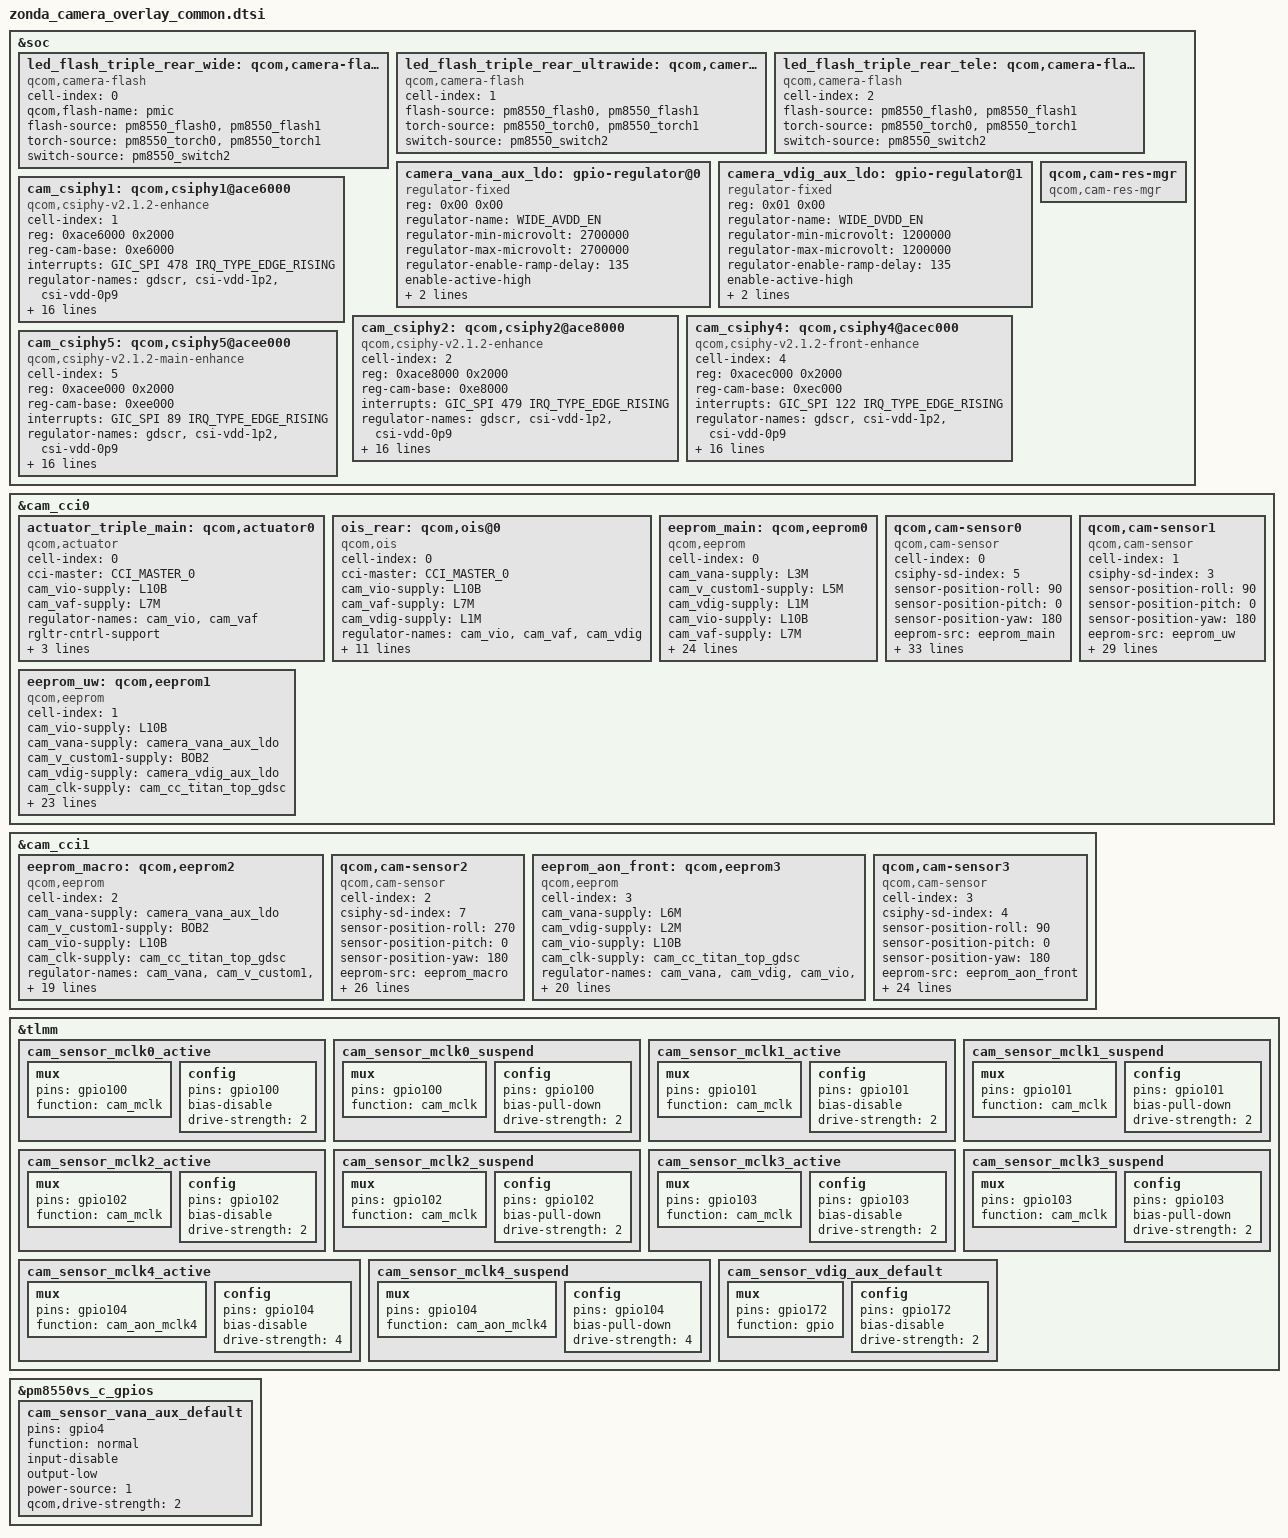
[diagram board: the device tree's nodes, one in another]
#include <dt-bindings/msm-camera.h>

&soc {
	led_flash_triple_rear_wide: qcom,camera-flash0 {
		cell-index = <0>;
		compatible = "qcom,camera-flash";
		qcom,flash-name = "pmic";
		flash-source = <&pm8550_flash0 &pm8550_flash1>;
		torch-source = <&pm8550_torch0 &pm8550_torch1>;
		switch-source = <&pm8550_switch2>;
		status = "ok";
	};

	led_flash_triple_rear_ultrawide: qcom,camera-flash1 {
		cell-index = <1>;
		compatible = "qcom,camera-flash";
		flash-source = <&pm8550_flash0 &pm8550_flash1>;
		torch-source = <&pm8550_torch0 &pm8550_torch1>;
		switch-source = <&pm8550_switch2>;
		status = "ok";
	};

	led_flash_triple_rear_tele: qcom,camera-flash2 {
		cell-index = <2>;
		compatible = "qcom,camera-flash";
		flash-source = <&pm8550_flash0 &pm8550_flash1>;
		torch-source = <&pm8550_torch0 &pm8550_torch1>;
		switch-source = <&pm8550_switch2>;
		status = "ok";
	};
	camera_vana_aux_ldo: gpio-regulator@0 {
		compatible = "regulator-fixed";
		reg = <0x00 0x00>;
		regulator-name = "WIDE_AVDD_EN";
		regulator-min-microvolt = <2700000>;
		regulator-max-microvolt = <2700000>;
		regulator-enable-ramp-delay = <135>;
		enable-active-high;
		gpio = <&pm8550vs_c_gpios 4 0>;
		pinctrl-names = "default";
		pinctrl-0 = <&cam_sensor_vana_aux_default>;
		//vin-supply = <&BOB>;
	};
	camera_vdig_aux_ldo: gpio-regulator@1 {
		compatible = "regulator-fixed";
		reg = <0x01 0x00>;
		regulator-name = "WIDE_DVDD_EN";
		regulator-min-microvolt = <1200000>;
		regulator-max-microvolt = <1200000>;
		regulator-enable-ramp-delay = <135>;
		enable-active-high;
		gpio = <&tlmm 172 0>;
		pinctrl-names = "default";
		pinctrl-0 = <&cam_sensor_vdig_aux_default>;
		//vin-supply = <&S4G>;
	};
	qcom,cam-res-mgr {
		compatible = "qcom,cam-res-mgr";
		status = "ok";
	};

	cam_csiphy1: qcom,csiphy1@ace6000 {
		cell-index = <1>;
		compatible = "qcom,csiphy-v2.1.2-enhance", "qcom,csiphy";
		reg = <0xace6000 0x2000>;
		reg-names = "csiphy";
		reg-cam-base = <0xe6000>;
		interrupt-names = "CSIPHY1";
		interrupts = <GIC_SPI 478 IRQ_TYPE_EDGE_RISING>;
		regulator-names = "gdscr", "csi-vdd-1p2", "csi-vdd-0p9";
		gdscr-supply = <&cam_cc_titan_top_gdsc>;
		csi-vdd-1p2-supply = <&L3E>;
		csi-vdd-0p9-supply = <&L1E>;
		rgltr-cntrl-support;
		rgltr-min-voltage = <0 1200000 875000>;
		rgltr-max-voltage = <0 1200000 925000>;
		rgltr-load-current = <0 18000 32200>;
		shared-clks = <1 0 0 0>;
		clock-names = "cphy_rx_clk_src",
			"csiphy1_clk",
			"csi1phytimer_clk_src",
			"csi1phytimer_clk";
		clocks = <&camcc CAM_CC_CPHY_RX_CLK_SRC>,
			<&camcc CAM_CC_CSIPHY1_CLK>,
			<&camcc CAM_CC_CSI1PHYTIMER_CLK_SRC>,
			<&camcc CAM_CC_CSI1PHYTIMER_CLK>;
		src-clock-name = "csi1phytimer_clk_src";
		clock-cntl-level = "lowsvs", "nominal";
		clock-rates =
			<400000000 0 400000000 0>,
			<480000000 0 400000000 0>;
		status = "ok";
	};

	cam_csiphy2: qcom,csiphy2@ace8000 {
		cell-index = <2>;
		compatible = "qcom,csiphy-v2.1.2-enhance", "qcom,csiphy";
		reg = <0xace8000 0x2000>;
		reg-names = "csiphy";
		reg-cam-base = <0xe8000>;
		interrupt-names = "CSIPHY2";
		interrupts = <GIC_SPI 479 IRQ_TYPE_EDGE_RISING>;
		regulator-names = "gdscr", "csi-vdd-1p2", "csi-vdd-0p9";
		gdscr-supply = <&cam_cc_titan_top_gdsc>;
		csi-vdd-1p2-supply = <&L3E>;
		csi-vdd-0p9-supply = <&L1E>;
		rgltr-cntrl-support;
		rgltr-min-voltage = <0 1200000 875000>;
		rgltr-max-voltage = <0 1200000 925000>;
		rgltr-load-current = <0 18000 32200>;
		shared-clks = <1 0 0 0>;
		clock-names = "cphy_rx_clk_src",
			"csiphy2_clk",
			"csi2phytimer_clk_src",
			"csi2phytimer_clk";
		clocks = <&camcc CAM_CC_CPHY_RX_CLK_SRC>,
			<&camcc CAM_CC_CSIPHY2_CLK>,
			<&camcc CAM_CC_CSI2PHYTIMER_CLK_SRC>,
			<&camcc CAM_CC_CSI2PHYTIMER_CLK>;
		src-clock-name = "csi2phytimer_clk_src";
		clock-cntl-level = "lowsvs", "nominal";
		clock-rates =
			<400000000 0 400000000 0>,
			<480000000 0 400000000 0>;
		status = "ok";
	};

	cam_csiphy4: qcom,csiphy4@acec000 {
		cell-index = <4>;
		compatible = "qcom,csiphy-v2.1.2-front-enhance", "qcom,csiphy";
		reg = <0xacec000 0x2000>;
		reg-names = "csiphy";
		reg-cam-base = <0xec000>;
		interrupt-names = "CSIPHY4";
		interrupts = <GIC_SPI 122 IRQ_TYPE_EDGE_RISING>;
		regulator-names = "gdscr", "csi-vdd-1p2", "csi-vdd-0p9";
		gdscr-supply = <&cam_cc_titan_top_gdsc>;
		csi-vdd-1p2-supply = <&L3E>;
		csi-vdd-0p9-supply = <&L1E>;
		rgltr-cntrl-support;
		rgltr-min-voltage = <0 1200000 875000>;
		rgltr-max-voltage = <0 1200000 925000>;
		rgltr-load-current = <0 18600 37900>;
		shared-clks = <1 0 0 0>;
		clock-names = "cphy_rx_clk_src",
			"csiphy4_clk",
			"csi4phytimer_clk_src",
			"csi4phytimer_clk";
		clocks = <&camcc CAM_CC_CPHY_RX_CLK_SRC>,
			<&camcc CAM_CC_CSIPHY4_CLK>,
			<&camcc CAM_CC_CSI4PHYTIMER_CLK_SRC>,
			<&camcc CAM_CC_CSI4PHYTIMER_CLK>;
		src-clock-name = "csi4phytimer_clk_src";
		clock-cntl-level = "lowsvs", "nominal";
		clock-rates =
			<400000000 0 400000000 0>,
			<480000000 0 400000000 0>;
		status = "ok";
	};

	cam_csiphy5: qcom,csiphy5@acee000 {
		cell-index = <5>;
		compatible = "qcom,csiphy-v2.1.2-main-enhance", "qcom,csiphy";
		reg = <0xacee000 0x2000>;
		reg-names = "csiphy";
		reg-cam-base = <0xee000>;
		interrupt-names = "CSIPHY5";
		interrupts = <GIC_SPI 89 IRQ_TYPE_EDGE_RISING>;
		regulator-names = "gdscr", "csi-vdd-1p2", "csi-vdd-0p9";
		gdscr-supply = <&cam_cc_titan_top_gdsc>;
		csi-vdd-1p2-supply = <&L3E>;
		csi-vdd-0p9-supply = <&L1E>;
		rgltr-cntrl-support;
		rgltr-min-voltage = <0 1200000 875000>;
		rgltr-max-voltage = <0 1200000 950000>;
		rgltr-load-current = <0 18000 32200>;
		shared-clks = <1 0 0 0>;
		clock-names = "cphy_rx_clk_src",
			"csiphy5_clk",
			"csi5phytimer_clk_src",
			"csi5phytimer_clk";
		clocks = <&camcc CAM_CC_CPHY_RX_CLK_SRC>,
			<&camcc CAM_CC_CSIPHY5_CLK>,
			<&camcc CAM_CC_CSI5PHYTIMER_CLK_SRC>,
			<&camcc CAM_CC_CSI5PHYTIMER_CLK>;
		src-clock-name = "csi5phytimer_clk_src";
		clock-cntl-level = "lowsvs", "nominal";
		clock-rates =
			<400000000 0 400000000 0>,
			<480000000 0 400000000 0>;
		status = "ok";
	};
};

&cam_cci0 {

    //main camera
	actuator_triple_main: qcom,actuator0 {
		cell-index = <0>;
		compatible = "qcom,actuator";
		cci-master = <CCI_MASTER_0>;
		cam_vio-supply = <&L10B>;
		cam_vaf-supply = <&L7M>;
		regulator-names = "cam_vio", "cam_vaf";
		rgltr-cntrl-support;
		rgltr-min-voltage = <1800000 2800000>;
		rgltr-max-voltage = <1800000 2800000>;
		rgltr-load-current = <600000 300000>;
		status = "ok";
	};

	ois_rear: qcom,ois@0{
		cell-index = <0>;
		compatible = "qcom,ois";
		cci-master = <CCI_MASTER_0>;
		cam_vio-supply = <&L10B>;
		cam_vaf-supply = <&L7M>;
		cam_vdig-supply = <&L1M>;
		regulator-names = "cam_vio", "cam_vaf", "cam_vdig";
		rgltr-cntrl-support;
		rgltr-min-voltage = <1800000 2800000 2800000>;
		rgltr-max-voltage = <1800000 2800000 2800000>;
		rgltr-load-current = <600000 300000 300000>;
		ois_gyro,position=<3>;
		ois_gyro,type=<3>;
		ois,type=<0>;
		ois,name="bu63169";
		ois_module,vendor=<1>;
		ois_actuator,vednor=<2>;
		ois,fw=<1>;
		status = "ok";
	};

	eeprom_main: qcom,eeprom0 {
		cell-index = <0>;
		compatible = "qcom,eeprom";
		cam_vana-supply = <&L3M>;
		cam_v_custom1-supply = <&L5M>;
		cam_vdig-supply = <&L1M>;
		cam_vio-supply = <&L10B>;
		cam_vaf-supply = <&L7M>;
		cam_clk-supply = <&cam_cc_titan_top_gdsc>;
		regulator-names = "cam_vana", "cam_v_custom1", "cam_vdig", "cam_vio", "cam_vaf",
		                  "cam_clk";
		rgltr-cntrl-support;
		rgltr-min-voltage = <2800000 1800000 1104000 1800000 2800000 0>;
		rgltr-max-voltage = <2800000 1800000 1104000 1800000 2800000 0>;
		rgltr-load-current = <300000 600000 1200000 600000 300000 0>;
		gpio-no-mux = <0>;
		pinctrl-names = "cam_default", "cam_suspend";
		pinctrl-0 = <&cam_sensor_mclk2_active
			&cam_sensor_active_rst1>;
		pinctrl-1 = <&cam_sensor_mclk2_suspend
			&cam_sensor_suspend_rst1>;
		gpios = <&tlmm 102 0>,
			<&tlmm 117 0>;
		gpio-reset = <1>;
		gpio-req-tbl-num = <0 1>;
		gpio-req-tbl-flags = <1 0>;
		gpio-req-tbl-label = "CAMIF_MCLK2",
					"CAM_RESET1";
		cci-master = <CCI_MASTER_0>;
		clocks = <&camcc CAM_CC_MCLK2_CLK>;
		clock-names = "cam_clk";
		clock-cntl-level = "nominal";
		clock-rates = <19200000>;
		status = "ok";
	};

	qcom,cam-sensor0 {
		cell-index = <0>;
		compatible = "qcom,cam-sensor";
		csiphy-sd-index = <5>;
		sensor-position-roll = <90>;
		sensor-position-pitch = <0>;
		sensor-position-yaw = <180>;
		eeprom-src = <&eeprom_main>;
		actuator-src = <&actuator_triple_main>;
		ois-src = <&ois_rear>;
		led-flash-src = <&led_flash_triple_rear_wide>;
		cam_vana-supply = <&L3M>;
		cam_v_custom1-supply = <&L5M>;
		cam_vdig-supply = <&L1M>;
		cam_vio-supply = <&L10B>;
		cam_vaf-supply = <&L7M>;
		cam_clk-supply = <&cam_cc_titan_top_gdsc>;
		regulator-names = "cam_vana", "cam_v_custom1", "cam_vdig", "cam_vio", "cam_vaf",
		                  "cam_clk";
		rgltr-cntrl-support;
		rgltr-min-voltage = <2800000 1800000 1104000 1800000 2800000 0>;
		rgltr-max-voltage = <2800000 1800000 1104000 1800000 2800000 0>;
		rgltr-load-current = <300000 600000 1200000 600000 300000 0>;
		gpio-no-mux = <0>;
		pinctrl-names = "cam_default", "cam_suspend";
		pinctrl-0 = <&cam_sensor_mclk2_active
			&cam_sensor_active_rst1>;
		pinctrl-1 = <&cam_sensor_mclk2_suspend
			&cam_sensor_suspend_rst1>;
		gpios = <&tlmm 102 0>,
			<&tlmm 117 0>;
		gpio-reset = <1>;
		gpio-req-tbl-num = <0 1>;
		gpio-req-tbl-flags = <1 0>;
		gpio-req-tbl-label = "CAMIF_MCLK2",
					"CAM_RESET1";
		cci-master = <CCI_MASTER_0>;
		clocks = <&camcc CAM_CC_MCLK2_CLK>;
		clock-names = "cam_clk";
		clock-cntl-level = "nominal";
		clock-rates = <19200000>;
		status = "ok";
		is-power-up-advance = <1>;
	};

	eeprom_uw: qcom,eeprom1 {
		cell-index = <1>;
		compatible = "qcom,eeprom";
		cam_vio-supply = <&L10B>;
		cam_vana-supply = <&camera_vana_aux_ldo>;
		cam_v_custom1-supply = <&BOB2>;
		cam_vdig-supply = <&camera_vdig_aux_ldo>;
		cam_clk-supply = <&cam_cc_titan_top_gdsc>;
		regulator-names = "cam_vio", "cam_vana", "cam_v_custom1", "cam_vdig", "cam_clk";
		rgltr-cntrl-support;
		rgltr-min-voltage = <1800000 2700000 2800000 1200000 0>;
		rgltr-max-voltage = <1800000 2700000 2800000 1200000 0>;
		rgltr-load-current = <150000 300000 300000 1000000 0>;
		gpio-no-mux = <0>;
		pinctrl-names = "cam_default", "cam_suspend";
		pinctrl-0 = <&cam_sensor_mclk1_active
				 &cam_sensor_active_rst2>;
		pinctrl-1 = <&cam_sensor_mclk1_suspend
				 &cam_sensor_suspend_rst2>;
		gpios = <&tlmm 101 0>,
			<&tlmm 118 0>;
		gpio-reset = <1>;
		gpio-req-tbl-num = <0 1>;
		gpio-req-tbl-flags = <1 0>;
		gpio-req-tbl-label = "CAMIF_MCLK1",
					"CAM_RESET2";
		cci-master = <CCI_MASTER_1>;
		clocks = <&camcc CAM_CC_MCLK1_CLK>;
		clock-names = "cam_clk";
		clock-cntl-level = "nominal";
		clock-rates = <19200000>;
		status = "ok";
	};

	qcom,cam-sensor1 {
		cell-index = <1>;
		compatible = "qcom,cam-sensor";
		csiphy-sd-index = <3>;
		sensor-position-roll = <90>;
		sensor-position-pitch = <0>;
		sensor-position-yaw = <180>;
		eeprom-src = <&eeprom_uw>;
		led-flash-src = <&led_flash_triple_rear_ultrawide>;
		cam_vio-supply = <&L10B>;
		cam_vana-supply = <&camera_vana_aux_ldo>;
		cam_v_custom1-supply = <&BOB2>;
		cam_vdig-supply = <&camera_vdig_aux_ldo>;
		cam_clk-supply = <&cam_cc_titan_top_gdsc>;
		regulator-names = "cam_vio", "cam_vana", "cam_v_custom1", "cam_vdig", "cam_clk";
		rgltr-cntrl-support;
		rgltr-min-voltage = <1800000 2700000 2800000 1200000 0>;
		rgltr-max-voltage = <1800000 2700000 2800000 1200000 0>;
		rgltr-load-current = <150000 300000 300000 1000000 0>;
		gpio-no-mux = <0>;
		pinctrl-names = "cam_default", "cam_suspend";
		pinctrl-0 = <&cam_sensor_mclk1_active
				 &cam_sensor_active_rst2>;
		pinctrl-1 = <&cam_sensor_mclk1_suspend
				 &cam_sensor_suspend_rst2>;
		gpios = <&tlmm 101 0>,
			<&tlmm 118 0>;
		gpio-reset = <1>;
		gpio-req-tbl-num = <0 1>;
		gpio-req-tbl-flags = <1 0>;
		gpio-req-tbl-label = "CAMIF_MCLK1",
					"CAM_RESET2";
		cci-master = <CCI_MASTER_1>;
		clocks = <&camcc CAM_CC_MCLK1_CLK>;
		clock-names = "cam_clk";
		clock-cntl-level = "nominal";
		clock-rates = <19200000>;
		status = "ok";
	};
};
&cam_cci1 {
	eeprom_macro: qcom,eeprom2 {
		cell-index = <2>;
		compatible = "qcom,eeprom";
		cam_vana-supply = <&camera_vana_aux_ldo>;
		cam_v_custom1-supply = <&BOB2>;
		cam_vio-supply = <&L10B>;
		cam_clk-supply = <&cam_cc_titan_top_gdsc>;
		regulator-names = "cam_vana", "cam_v_custom1", "cam_vio", "cam_clk";
		rgltr-cntrl-support;
		rgltr-min-voltage = <2700000 2800000 1800000 0>;
		rgltr-max-voltage = <2700000 2800000 1800000 0>;
		rgltr-load-current = <300000 300000 150000 0>;
		gpio-no-mux = <0>;
		pinctrl-names = "cam_default", "cam_suspend";
		pinctrl-0 = <&cam_sensor_mclk0_active
				 &cam_sensor_active_rst3>;
		pinctrl-1 = <&cam_sensor_mclk0_suspend
				 &cam_sensor_suspend_rst3>;
		gpios = <&tlmm 100 0>,
			<&tlmm 119 0>;
		gpio-reset = <1>;
		gpio-req-tbl-num = <0 1>;
		gpio-req-tbl-flags = <1 0>;
		gpio-req-tbl-label = "CAMIF_MCLK0",
					"CAM_RESET3";
		cci-master = <CCI_MASTER_0>;
		clocks = <&camcc CAM_CC_MCLK0_CLK>;
		clock-names = "cam_clk";
		clock-cntl-level = "nominal";
		clock-rates = <19200000>;
		status = "ok";
	};

	// GC02M1
	qcom,cam-sensor2 {
		cell-index = <2>;
		compatible = "qcom,cam-sensor";
		csiphy-sd-index = <7>;
		sensor-position-roll = <270>;
		sensor-position-pitch = <0>;
		sensor-position-yaw = <180>;
		eeprom-src = <&eeprom_macro>;
		led-flash-src = <&led_flash_triple_rear_tele>;
		cam_vana-supply = <&camera_vana_aux_ldo>;
		cam_v_custom1-supply = <&BOB2>;
		cam_vio-supply = <&L10B>;
		cam_clk-supply = <&cam_cc_titan_top_gdsc>;
		regulator-names = "cam_vana", "cam_v_custom1", "cam_vio", "cam_clk";
		rgltr-cntrl-support;
		aon-user;
		rgltr-min-voltage = <2700000 2800000 1800000 0>;
		rgltr-max-voltage = <2700000 2800000 1800000 0>;
		rgltr-load-current = <300000 300000 150000 0>;
		gpio-no-mux = <0>;
		pinctrl-names = "cam_default", "cam_suspend";
		pinctrl-0 = <&cam_sensor_mclk0_active
				 &cam_sensor_active_rst3>;
		pinctrl-1 = <&cam_sensor_mclk0_suspend
				 &cam_sensor_suspend_rst3>;
		gpios = <&tlmm 100 0>,
			<&tlmm 119 0>;
		gpio-reset = <1>;
		gpio-req-tbl-num = <0 1>;
		gpio-req-tbl-flags = <1 0>;
		gpio-req-tbl-label = "CAMIF_MCLK0",
					"CAM_RESET3";
		cci-master = <CCI_MASTER_0>;
		clocks = <&camcc CAM_CC_MCLK0_CLK>;
		clock-names = "cam_clk";
		clock-cntl-level = "nominal";
		clock-rates = <19200000>;
		status = "ok";
	};

	eeprom_aon_front: qcom,eeprom3 {
		cell-index = <3>;
		compatible = "qcom,eeprom";
		cam_vana-supply = <&L6M>;
		cam_vdig-supply = <&L2M>;
		cam_vio-supply = <&L10B>;
		cam_clk-supply = <&cam_cc_titan_top_gdsc>;
		regulator-names = "cam_vana", "cam_vdig", "cam_vio", "cam_clk";
		rgltr-cntrl-support;
		aon-user;
		rgltr-min-voltage = <2800000 1050000 1800000 0>;
		rgltr-max-voltage = <2800000 1050000 1800000 0>;
		rgltr-load-current = <300000 1000000 150000 0>;
		gpio-no-mux = <0>;
		pinctrl-names = "cam_default", "cam_suspend";
		pinctrl-0 = <&cam_sensor_mclk4_active
				 &cam_sensor_active_rst4>;
		pinctrl-1 = <&cam_sensor_mclk4_suspend
				 &cam_sensor_suspend_rst4>;
		gpios = <&tlmm 104 0>,
			<&tlmm 120 0>;
		gpio-reset = <1>;
		gpio-req-tbl-num = <0 1>;
		gpio-req-tbl-flags = <1 0>;
		gpio-req-tbl-label = "CAMIF_MCLK4",
					"CAM_RESET4";
		cci-master = <CCI_MASTER_1>;
		clocks = <&camcc CAM_CC_MCLK4_CLK>;
		clock-names = "cam_clk";
		clock-cntl-level = "nominal";
		clock-rates = <19200000>;
		status = "ok";
	};

	// S5K3P9
	qcom,cam-sensor3 {
		cell-index = <3>;
		compatible = "qcom,cam-sensor";
		csiphy-sd-index = <4>;
		sensor-position-roll = <90>;
		sensor-position-pitch = <0>;
		sensor-position-yaw = <180>;
		eeprom-src = <&eeprom_aon_front>;
		//actuator-src = <&actuator_triple_tele>;
		//led-flash-src = <&led_flash_triple_rear_tele>;
		cam_vana-supply = <&L6M>;
		cam_vio-supply = <&L10B>;
		cam_vdig-supply = <&L2M>;
		cam_clk-supply = <&cam_cc_titan_top_gdsc>;
		regulator-names = "cam_vana", "cam_vio", "cam_vdig", "cam_clk";
		rgltr-cntrl-support;
		rgltr-min-voltage = <2800000 1800000 1050000 0>;
		rgltr-max-voltage = <2800000 1800000 1050000 0>;
		rgltr-load-current = <300000 150000 1000000 0>;
		gpio-no-mux = <0>;
		pinctrl-names = "cam_default", "cam_suspend";
		pinctrl-0 = <&cam_sensor_mclk4_active
				 &cam_sensor_active_rst4>;
		pinctrl-1 = <&cam_sensor_mclk4_suspend
				 &cam_sensor_suspend_rst4>;
		gpios = <&tlmm 104 0>,
			<&tlmm 120 0>;
		gpio-reset = <1>;
		gpio-req-tbl-num = <0 1>;
		gpio-req-tbl-flags = <1 0>;
		gpio-req-tbl-label = "CAMIF_MCLK4",
					"CAM_RESET4";
		cci-master = <CCI_MASTER_1>;
		clocks = <&camcc CAM_CC_MCLK4_CLK>;
		clock-names = "cam_clk";
		clock-cntl-level = "nominal";
		clock-rates = <19200000>;
		status = "ok";
	};
};
&tlmm {
	cam_sensor_mclk0_active: cam_sensor_mclk0_active {
		/* MCLK0 */
		mux {
			pins = "gpio100";
			function = "cam_mclk";
		};

		config {
			pins = "gpio100";
			bias-disable; /* No PULL */
			drive-strength = <2>; /* 2 MA */
		};
	};

	cam_sensor_mclk0_suspend: cam_sensor_mclk0_suspend {
		/* MCLK0 */
		mux {
			pins = "gpio100";
			function = "cam_mclk";
		};

		config {
			pins = "gpio100";
			bias-pull-down; /* PULL DOWN */
			drive-strength = <2>; /* 2 MA */
		};
	};

	cam_sensor_mclk1_active: cam_sensor_mclk1_active {
		/* MCLK1 */
		mux {
			pins = "gpio101";
			function = "cam_mclk";
		};

		config {
			pins = "gpio101";
			bias-disable; /* No PULL */
			drive-strength = <2>; /* 2 MA */
		};
	};

	cam_sensor_mclk1_suspend: cam_sensor_mclk1_suspend {
		/* MCLK1 */
		mux {
			pins = "gpio101";
			function = "cam_mclk";
		};

		config {
			pins = "gpio101";
			bias-pull-down; /* PULL DOWN */
			drive-strength = <2>; /* 2 MA */
		};
	};

	cam_sensor_mclk2_active: cam_sensor_mclk2_active {
		/* MCLK2 */
		mux {
			pins = "gpio102";
			function = "cam_mclk";
		};

		config {
			pins = "gpio102";
			bias-disable; /* No PULL */
			drive-strength = <2>; /* 2 MA */
		};
	};

	cam_sensor_mclk2_suspend: cam_sensor_mclk2_suspend {
		/* MCLK2 */
		mux {
			pins = "gpio102";
			function = "cam_mclk";
		};

		config {
			pins = "gpio102";
			bias-pull-down; /* PULL DOWN */
			drive-strength = <2>; /* 2 MA */
		};
	};

	cam_sensor_mclk3_active: cam_sensor_mclk3_active {
		/* MCLK3 */
		mux {
			pins = "gpio103";
			function = "cam_mclk";
		};

		config {
			pins = "gpio103";
			bias-disable; /* No PULL */
			drive-strength = <2>; /* 2 MA */
		};
	};

	cam_sensor_mclk3_suspend: cam_sensor_mclk3_suspend {
		/* MCLK3 */
		mux {
			pins = "gpio103";
			function = "cam_mclk";
		};

		config {
			pins = "gpio103";
			bias-pull-down; /* PULL DOWN */
			drive-strength = <2>; /* 2 MA */
		};
	};

	cam_sensor_mclk4_active: cam_sensor_mclk4_active {
		/* MCLK4 */
		mux {
			pins = "gpio104";
			function = "cam_aon_mclk4";
		};

		config {
			pins = "gpio104";
			bias-disable; /* No PULL */
			drive-strength = <4>; /* 4 MA */
		};
	};

	cam_sensor_mclk4_suspend: cam_sensor_mclk4_suspend {
		/* MCLK4 */
		mux {
			pins = "gpio104";
			function = "cam_aon_mclk4";
		};

		config {
			pins = "gpio104";
			bias-pull-down; /* PULL DOWN */
			drive-strength = <4>; /* 4 MA */
		};
	};

	cam_sensor_vdig_aux_default: cam_sensor_vdig_aux_default {
		/*  VIO LDO */
		mux {
			pins = "gpio172";
			function = "gpio";
		};

		config {
			pins = "gpio172";
			bias-disable; /* No PULL */
			drive-strength = <2>; /* 2 MA */
		};
	};
};
&pm8550vs_c_gpios {
	cam_sensor_vana_aux_default: cam_sensor_vana_aux_default {
		pins = "gpio4";
		function = "normal";
		input-disable;
		output-low;
		power-source = <1>; /* 2.7V */
		qcom,drive-strength = <2>;
	};
};
